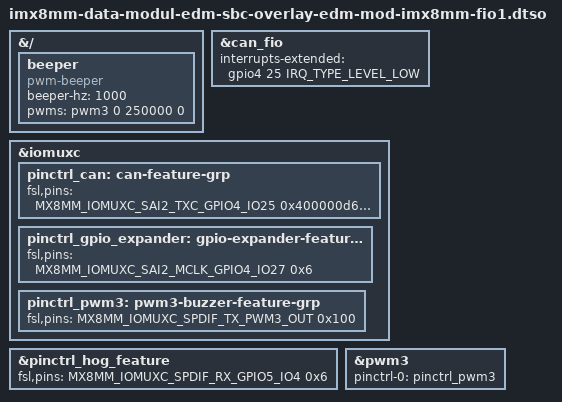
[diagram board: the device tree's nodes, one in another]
// SPDX-License-Identifier: (GPL-2.0+ OR MIT)
/*
 * Copyright 2022-2026 Marek Vasut
 */
/dts-v1/;
/plugin/;

#include "imx8mm-pinfunc.h"
#include "imx8mm-data-modul-edm-sbc-overlay-edm-mod-imx8mm-fio1.dtsi"

&{/} {
	beeper {
		compatible = "pwm-beeper";
		beeper-hz = <1000>;
		pwms = <&pwm3 0 250000 0>;
	};
};

&can_fio {
	interrupts-extended = <&gpio4 25 IRQ_TYPE_LEVEL_LOW>;
};

&iomuxc {
	pinctrl_can: can-feature-grp {
		fsl,pins = <
			/* CAN_INT# */
			MX8MM_IOMUXC_SAI2_TXC_GPIO4_IO25		0x400000d6
			/* CAN_RST# */
			MX8MM_IOMUXC_SAI2_TXD0_GPIO4_IO26		0x6
		>;
	};

	pinctrl_gpio_expander: gpio-expander-feature-grp {
		fsl,pins = <
			/* GPIO4_IO27 */
			MX8MM_IOMUXC_SAI2_MCLK_GPIO4_IO27		0x6
		>;
	};

	pinctrl_pwm3: pwm3-buzzer-feature-grp {
		fsl,pins = <
			/* Buzzer PWM output */
			MX8MM_IOMUXC_SPDIF_TX_PWM3_OUT			0x100
		>;
	};
};

&pinctrl_hog_feature {
	fsl,pins = <
		/* GPIO5_IO04 */
		MX8MM_IOMUXC_SPDIF_RX_GPIO5_IO4			0x6
	>;
};

&pwm3 {
	pinctrl-names = "default";
	pinctrl-0 = <&pinctrl_pwm3>;
	status = "okay";
};
